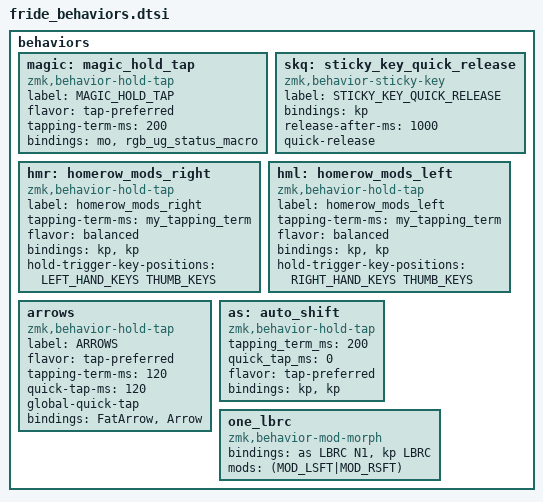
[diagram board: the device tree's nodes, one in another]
behaviors {

    magic: magic_hold_tap {
            compatible = "zmk,behavior-hold-tap";
            label = "MAGIC_HOLD_TAP";
            #binding-cells = <2>;
            flavor = "tap-preferred";
            tapping-term-ms = <200>;
            bindings = <&mo>, <&rgb_ug_status_macro>;
    };


   skq: sticky_key_quick_release {
      compatible = "zmk,behavior-sticky-key";
      label = "STICKY_KEY_QUICK_RELEASE";
      #binding-cells = <1>;
      bindings = <&kp>;
      release-after-ms = <1000>;
      quick-release;
    };

    // Home Row Mods
    hmr: homerow_mods_right { // use on right hand to mod left
        compatible = "zmk,behavior-hold-tap";
        label = "homerow_mods_right";
        #binding-cells = <2>;
        tapping-term-ms = <my_tapping_term>;
        flavor = "balanced";
        bindings = <&kp>, <&kp>;
        hold-trigger-key-positions = <LEFT_HAND_KEYS THUMB_KEYS>; // left hand allowed
    };

    hml: homerow_mods_left { // use on left hand to mod right
        compatible = "zmk,behavior-hold-tap";
        label = "homerow_mods_left";
        #binding-cells = <2>;
        tapping-term-ms = <my_tapping_term>;
        flavor = "balanced";
        bindings = <&kp>, <&kp>;
        hold-trigger-key-positions = <RIGHT_HAND_KEYS THUMB_KEYS>; // right hand allowed but  not magic!
    };

    arrows: arrows {
        compatible = "zmk,behavior-hold-tap";
        label = "ARROWS";
        #binding-cells = <2>;
        flavor = "tap-preferred";
        tapping-term-ms = <120>;
        quick-tap-ms = <120>;
        global-quick-tap;
        bindings = <&FatArrow>, <&Arrow>;
    };

     as: auto_shift {
        compatible = "zmk,behavior-hold-tap";
        #binding-cells = <2>;
        tapping_term_ms = <200>;
        quick_tap_ms = <0>;
        flavor = "tap-preferred";
        bindings = <&kp>, <&kp>;
    };
// TODO make this a macro!
      one_lbrc: one_lbrc {
        compatible = "zmk,behavior-mod-morph";
        #binding-cells = <0>;
        bindings = <&as LBRC N1>, <&kp LBRC>;
        mods = <(MOD_LSFT|MOD_RSFT)>;
    };

};
